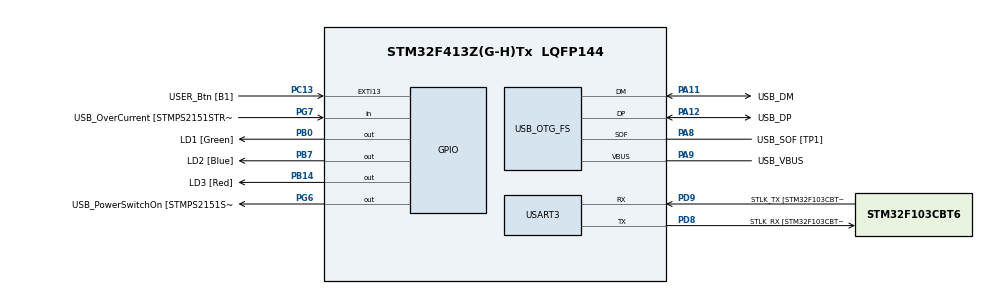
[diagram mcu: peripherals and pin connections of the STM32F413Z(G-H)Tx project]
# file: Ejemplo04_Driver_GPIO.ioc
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Mcu.Family=STM32F4
Mcu.Name=STM32F413Z(G-H)Tx
Mcu.Package=LQFP144
NVIC.PriorityGroup=NVIC_PRIORITYGROUP_4
PA10.GPIO_Label=USB_ID
PA10.Signal=USB_OTG_FS_ID
PA11.GPIO_Label=USB_DM
PA11.Mode=Device_Only
PA11.Signal=USB_OTG_FS_DM
PA12.GPIO_Label=USB_DP
PA12.Mode=Device_Only
PA12.Signal=USB_OTG_FS_DP
PA13.GPIO_Label=TMS
PA13.Mode=Serial_Wire
PA13.Signal=SYS_JTMS-SWDIO
PA14.GPIO_Label=TCK
PA14.Mode=Serial_Wire
PA14.Signal=SYS_JTCK-SWCLK
PA8.GPIO_Label=USB_SOF [TP1]
PA8.Mode=Activate_SOF_FS
PA8.Signal=USB_OTG_FS_SOF
PA9.GPIO_Label=USB_VBUS
PA9.Mode=Activate_VBUS
PA9.Signal=USB_OTG_FS_VBUS
PB0.GPIO_Label=LD1 [Green]
PB0.Signal=GPIO_Output
PB14.GPIO_Label=LD3 [Red]
PB14.Signal=GPIO_Output
PB3.GPIO_Label=SWO
PB3.Signal=SYS_JTDO-SWO
PB7.GPIO_Label=LD2 [Blue]
PB7.Signal=GPIO_Output
PC13.GPIO_Label=USER_Btn [B1]
PC13.Signal=GPXTI13
PC14-OSC32_IN.Mode=LSE-External-Oscillator
PC14-OSC32_IN.Signal=RCC_OSC32_IN
PC15-OSC32_OUT.Mode=LSE-External-Oscillator
PC15-OSC32_OUT.Signal=RCC_OSC32_OUT
PD8.GPIO_Label=STLK_RX [STM32F103CBT6_PA3]
PD8.Mode=Asynchronous
PD8.Signal=USART3_TX
PD9.GPIO_Label=STLK_TX [STM32F103CBT6_PA2]
PD9.Mode=Asynchronous
PD9.Signal=USART3_RX
PG6.GPIO_Label=USB_PowerSwitchOn [STMPS2151STR_EN]
PG6.Signal=GPIO_Output
PG7.GPIO_Label=USB_OverCurrent [STMPS2151STR_FAULT]
PG7.Signal=GPIO_Input
PH0\ -\ OSC_IN.GPIO_Label=MCO
PH0\ -\ OSC_IN.Mode=HSE-External-Clock-Source
PH0\ -\ OSC_IN.Signal=RCC_OSC_IN
PH1\ -\ OSC_OUT.Mode=HSE-External-Clock-Source
PH1\ -\ OSC_OUT.Signal=RCC_OSC_OUT
ProjectManager.HeapSize=0x200
ProjectManager.StackSize=0x400
ProjectManager.TargetToolchain=STM32CubeIDE
RCC.48MHZClocksFreq_Value=24000000
RCC.AHBFreq_Value=96000000
RCC.APB1CLKDivider=RCC_HCLK_DIV2
RCC.APB1Freq_Value=48000000
RCC.APB1TimFreq_Value=96000000
RCC.APB2Freq_Value=96000000
RCC.APB2TimFreq_Value=96000000
RCC.CortexFreq_Value=96000000
RCC.HCLKFreq_Value=96000000
RCC.HSE_VALUE=8000000
RCC.HSI_VALUE=16000000
RCC.PLLM=8
RCC.PLLMUL=RCC_PLL_MUL9
RCC.PLLN=384
RCC.PLLP=RCC_PLLP_DIV4
RCC.PLLQ=8
RCC.PRESCALERUSB=RCC_USBCLKSOURCE_PLL_DIV1_5
RCC.SYSCLKFreq_VALUE=96000000
RCC.SYSCLKSource=RCC_SYSCLKSOURCE_PLLCLK
RCC.SYSCLKSourceVirtual=RCC_SYSCLKSOURCE_PLLCLK
RCC.USBFreq_Value=48000000
RCC.VCOOutputFreq_Value=384000000
USART3.VirtualMode=VM_ASYNC
USB_OTG_FS.VirtualMode=Device_Only
board=NUCLEO-F413ZH

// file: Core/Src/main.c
/* USER CODE BEGIN Header */
/**
  ******************************************************************************
  * @file           : main.c
  * @brief          : Main program body
  ******************************************************************************
  * @attention
  *
  * Copyright (c) 2024 STMicroelectronics.
  * All rights reserved.
  *
  * This software is licensed under terms that can be found in the LICENSE file
  * in the root directory of this software component.
  * If no LICENSE file comes with this software, it is provided AS-IS.
  *
  ******************************************************************************
  */
/* USER CODE END Header */
#include "main.h"
#include "API_GPIO.h"

int main(void)
{

  /* MCU Configuration--------------------------------------------------------*/

  /* Reset of all peripherals, Initializes the Flash interface and the Systick. */
  HAL_Init();

  /* USER CODE BEGIN Init */
  uint16_t LEDS[3] = {LD1_Pin, LD2_Pin, LD3_Pin}; /*Creo vector de LEDs de usuario*/
  uint16_t User_Button;
  /* USER CODE END Init */

  /* Configure the system clock */
  SystemClock_Config();

  /* Initialize all configured peripherals */
  MX_GPIO_Init();
  MX_USART3_UART_Init();
  MX_USB_OTG_FS_PCD_Init();

  /* Infinite loop */
  /* USER CODE BEGIN WHILE */
  while (1)
  {
	User_Button = readButton_GPIO();
    if (User_Button == 1)
	{

      writeLedOff_GPIO(LEDS[2]);
	  for (uint8_t i = 0; i < 2; i++)
	  {
		writeLedOn_GPIO(LEDS[i]);
	  	HAL_Delay(200);
	  	writeLedOff_GPIO(LEDS[i]);
	  	HAL_Delay(200);
	  }
	}
    else
    {
    	writeLedOn_GPIO(LEDS[2]);
    }
  }
    /* USER CODE END WHILE */

}

void Error_Handler(void)
{
  __disable_irq();
  while (1)
  {
  }
}
